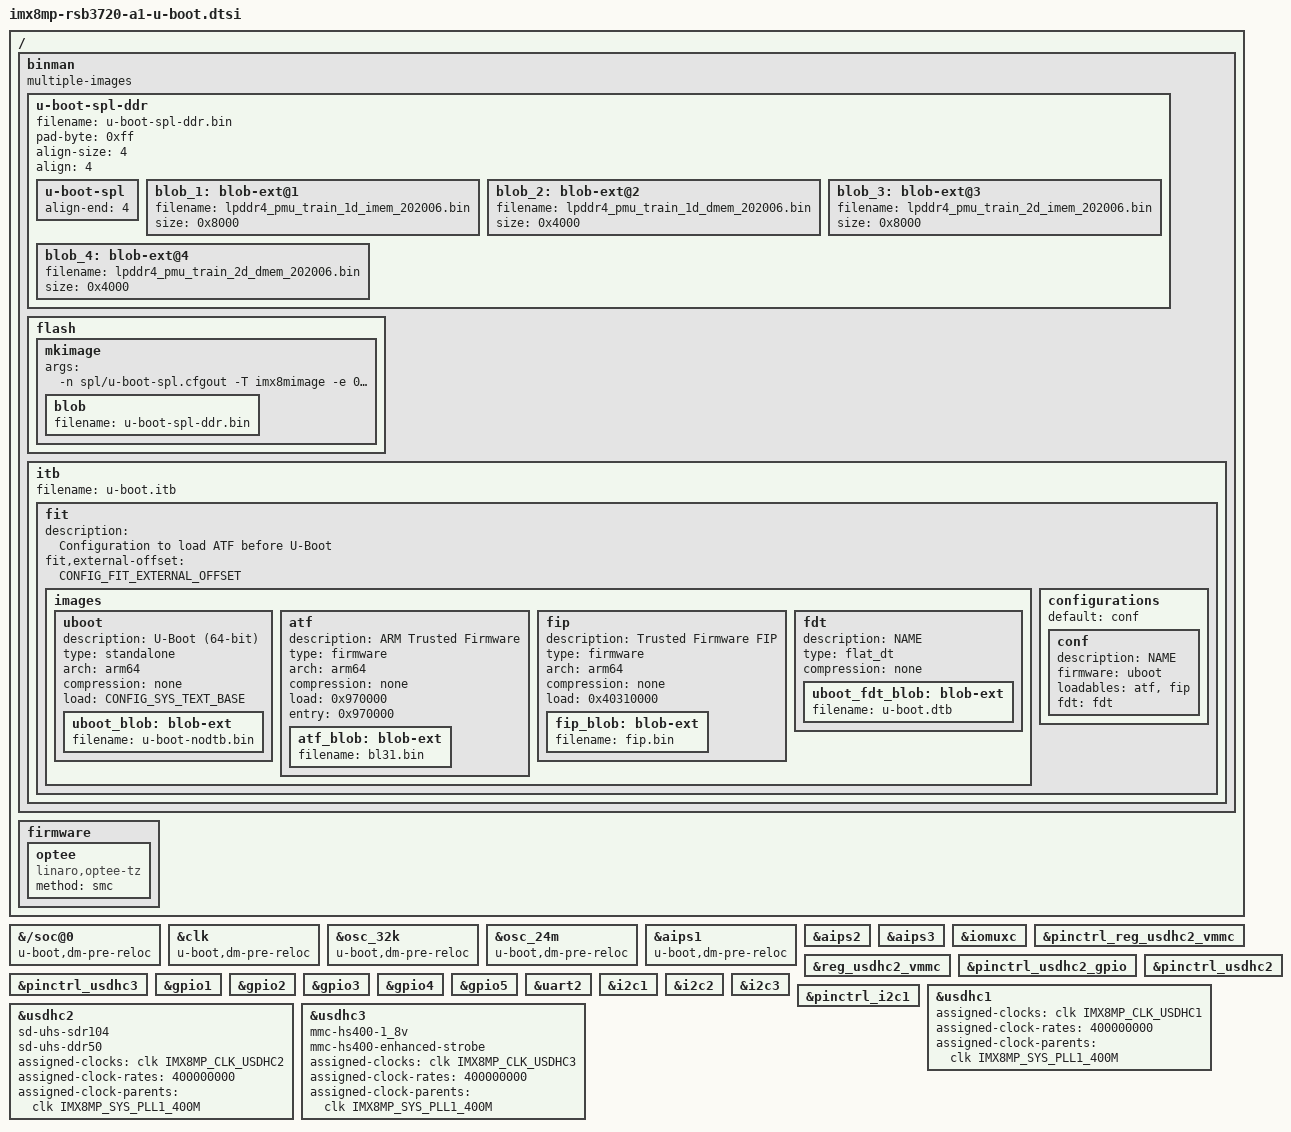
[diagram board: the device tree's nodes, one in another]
// SPDX-License-Identifier: GPL-2.0+
/*
 * Copyright 2019 NXP
 * Copyright 2021 Linaro
 */

/ {
	binman: binman {
		multiple-images;
	};

	firmware {
		optee {
			compatible = "linaro,optee-tz";
			method = "smc";
		};
	};
};

&{/soc@0} {
	u-boot,dm-pre-reloc;
	u-boot,dm-spl;
};

&clk {
	u-boot,dm-spl;
	u-boot,dm-pre-reloc;
	/delete-property/ assigned-clocks;
	/delete-property/ assigned-clock-parents;
	/delete-property/ assigned-clock-rates;

};

&osc_32k {
	u-boot,dm-spl;
	u-boot,dm-pre-reloc;
};

&osc_24m {
	u-boot,dm-spl;
	u-boot,dm-pre-reloc;
};

&aips1 {
	u-boot,dm-spl;
	u-boot,dm-pre-reloc;
};

&aips2 {
	u-boot,dm-spl;
};

&aips3 {
	u-boot,dm-spl;
};

&iomuxc {
	u-boot,dm-spl;
};

&pinctrl_reg_usdhc2_vmmc {
	u-boot,dm-spl;
};

&reg_usdhc2_vmmc {
	u-boot,dm-spl;
};

&pinctrl_usdhc2_gpio {
	u-boot,dm-spl;
};

&pinctrl_usdhc2 {
	u-boot,dm-spl;
};

&pinctrl_usdhc3 {
	u-boot,dm-spl;
};

&gpio1 {
	u-boot,dm-spl;
};

&gpio2 {
	u-boot,dm-spl;
};

&gpio3 {
	u-boot,dm-spl;
};

&gpio4 {
	u-boot,dm-spl;
};

&gpio5 {
	u-boot,dm-spl;
};

&uart2 {
	u-boot,dm-spl;
};

&i2c1 {
	u-boot,dm-spl;
};

&i2c2 {
	u-boot,dm-spl;
};

&i2c3 {
	u-boot,dm-spl;
};

&pinctrl_i2c1 {
	u-boot,dm-spl;
};

&usdhc1 {
	u-boot,dm-spl;
	assigned-clocks = <&clk IMX8MP_CLK_USDHC1>;
	assigned-clock-rates = <400000000>;
	assigned-clock-parents = <&clk IMX8MP_SYS_PLL1_400M>;
};

&usdhc2 {
	u-boot,dm-spl;
	sd-uhs-sdr104;
	sd-uhs-ddr50;
	assigned-clocks = <&clk IMX8MP_CLK_USDHC2>;
	assigned-clock-rates = <400000000>;
	assigned-clock-parents = <&clk IMX8MP_SYS_PLL1_400M>;
};

&usdhc3 {
	u-boot,dm-spl;
	mmc-hs400-1_8v;
	mmc-hs400-enhanced-strobe;
	assigned-clocks = <&clk IMX8MP_CLK_USDHC3>;
	assigned-clock-rates = <400000000>;
	assigned-clock-parents = <&clk IMX8MP_SYS_PLL1_400M>;
};

&binman {
	 u-boot-spl-ddr {
		filename = "u-boot-spl-ddr.bin";
		pad-byte = <0xff>;
		align-size = <4>;
		align = <4>;

		u-boot-spl {
			align-end = <4>;
		};

		blob_1: blob-ext@1 {
			filename = "lpddr4_pmu_train_1d_imem_202006.bin";
			size = <0x8000>;
		};

		blob_2: blob-ext@2 {
			filename = "lpddr4_pmu_train_1d_dmem_202006.bin";
			size = <0x4000>;
		};

		blob_3: blob-ext@3 {
			filename = "lpddr4_pmu_train_2d_imem_202006.bin";
			size = <0x8000>;
		};

		blob_4: blob-ext@4 {
			filename = "lpddr4_pmu_train_2d_dmem_202006.bin";
			size = <0x4000>;
		};
	};

	flash {
		mkimage {
			args = "-n spl/u-boot-spl.cfgout -T imx8mimage -e 0x920000";

			blob {
				filename = "u-boot-spl-ddr.bin";
			};
		};
	};

	itb {
		filename = "u-boot.itb";

		fit {
			description = "Configuration to load ATF before U-Boot";
			#address-cells = <1>;
			fit,external-offset = <CONFIG_FIT_EXTERNAL_OFFSET>;

			images {
				uboot {
					description = "U-Boot (64-bit)";
					type = "standalone";
					arch = "arm64";
					compression = "none";
					load = <CONFIG_SYS_TEXT_BASE>;

					uboot_blob: blob-ext {
						filename = "u-boot-nodtb.bin";
					};
				};

				atf {
					description = "ARM Trusted Firmware";
					type = "firmware";
					arch = "arm64";
					compression = "none";
					load = <0x970000>;
					entry = <0x970000>;

					atf_blob: blob-ext {
						filename = "bl31.bin";
					};
				};

				fip {
					description = "Trusted Firmware FIP";
					type = "firmware";
					arch = "arm64";
					compression = "none";
					load = <0x40310000>;

					fip_blob: blob-ext{
						filename = "fip.bin";
					};
				};

				fdt {
					description = "NAME";
					type = "flat_dt";
					compression = "none";

					uboot_fdt_blob: blob-ext {
						filename = "u-boot.dtb";
					};
				};
			};

			configurations {
				default = "conf";

				conf {
					description = "NAME";
					firmware = "uboot";
					loadables = "atf", "fip";
					fdt = "fdt";
				};
			};
		};
	};
};
